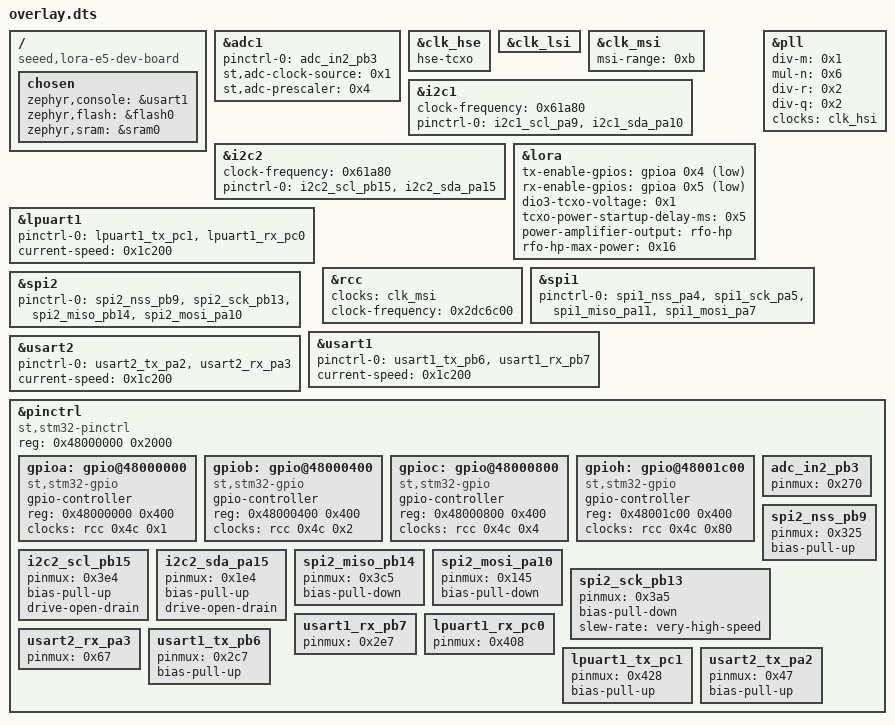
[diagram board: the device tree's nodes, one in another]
/ {
	compatible = "seeed,lora-e5-dev-board";
	chosen {
		zephyr,console = &usart1;
		zephyr,flash = &flash0;
		zephyr,sram = &sram0;
	};
};
&adc1{
	status = "okay";
	pinctrl-0 = < &adc_in2_pb3 >;
	pinctrl-names = "default";
	st,adc-clock-source = < 0x1 >;
	st,adc-prescaler = < 0x4 >;
};
&clk_hse{
	hse-tcxo;
};
&clk_lsi{
	status = "okay";
};
&clk_msi{
	msi-range = < 0xb >;
	status = "okay";
};
&i2c1{
	clock-frequency = < 0x61a80 >;
	status = "okay";
	pinctrl-0 = < &i2c1_scl_pa9 &i2c1_sda_pa10 >;
	pinctrl-names = "default";
};
&i2c2{
	clock-frequency = < 0x61a80 >;
	status = "okay";
	pinctrl-0 = < &i2c2_scl_pb15 &i2c2_sda_pa15 >;
	pinctrl-names = "default";
};
&lora{
	tx-enable-gpios = < &gpioa 0x4 0x1 >;
	rx-enable-gpios = < &gpioa 0x5 0x1 >;
	dio3-tcxo-voltage = < 0x1 >;
	tcxo-power-startup-delay-ms = < 0x5 >;
	power-amplifier-output = "rfo-hp";
	rfo-hp-max-power = < 0x16 >;
};
&lpuart1{
	status = "okay";
	pinctrl-0 = < &lpuart1_tx_pc1 &lpuart1_rx_pc0 >;
	pinctrl-names = "default";
	current-speed = < 0x1c200 >;
};
&pll{
	status = "okay";
	div-m = < 0x1 >;
	mul-n = < 0x6 >;
	div-r = < 0x2 >;
	div-q = < 0x2 >;
	clocks = < &clk_hsi >;
};
&rcc{
	clocks = < &clk_msi >;
	clock-frequency = < 0x2dc6c00 >;
};
&spi1{
	status = "okay";
	pinctrl-0 = < &spi1_nss_pa4 &spi1_sck_pa5 &spi1_miso_pa11 &spi1_mosi_pa7 >;
	pinctrl-names = "default";
};
&spi2{
	status = "okay";
	pinctrl-0 = < &spi2_nss_pb9 &spi2_sck_pb13 &spi2_miso_pb14 &spi2_mosi_pa10 >;
	pinctrl-names = "default";
};
&usart1{
	status = "okay";
	pinctrl-0 = < &usart1_tx_pb6 &usart1_rx_pb7 >;
	pinctrl-names = "default";
	current-speed = < 0x1c200 >;
};
&usart2{
	status = "okay";
	pinctrl-0 = < &usart2_tx_pa2 &usart2_rx_pa3 >;
	pinctrl-names = "default";
	current-speed = < 0x1c200 >;
};
&pinctrl{
	compatible = "st,stm32-pinctrl";
	#address-cells = < 0x1 >;
	#size-cells = < 0x1 >;
	reg = < 0x48000000 0x2000 >;
	gpioa: gpio@48000000 {
		compatible = "st,stm32-gpio";
		gpio-controller;
		#gpio-cells = < 0x2 >;
		reg = < 0x48000000 0x400 >;
		clocks = < &rcc 0x4c 0x1 >;
	};
	gpiob: gpio@48000400 {
		compatible = "st,stm32-gpio";
		gpio-controller;
		#gpio-cells = < 0x2 >;
		reg = < 0x48000400 0x400 >;
		clocks = < &rcc 0x4c 0x2 >;
	};
	gpioc: gpio@48000800 {
		compatible = "st,stm32-gpio";
		gpio-controller;
		#gpio-cells = < 0x2 >;
		reg = < 0x48000800 0x400 >;
		clocks = < &rcc 0x4c 0x4 >;
	};
	gpioh: gpio@48001c00 {
		compatible = "st,stm32-gpio";
		gpio-controller;
		#gpio-cells = < 0x2 >;
		reg = < 0x48001c00 0x400 >;
		clocks = < &rcc 0x4c 0x80 >;
	};
	adc_in2_pb3: adc_in2_pb3 {
		pinmux = < 0x270 >;
	};
	i2c2_scl_pb15: i2c2_scl_pb15 {
		pinmux = < 0x3e4 >;
		bias-pull-up;
		drive-open-drain;
	};
	i2c2_sda_pa15: i2c2_sda_pa15 {
		pinmux = < 0x1e4 >;
		bias-pull-up;
		drive-open-drain;
	};
	spi2_miso_pb14: spi2_miso_pb14 {
		pinmux = < 0x3c5 >;
		bias-pull-down;
	};
	spi2_mosi_pa10: spi2_mosi_pa10 {
		pinmux = < 0x145 >;
		bias-pull-down;
	};
	spi2_nss_pb9: spi2_nss_pb9 {
		pinmux = < 0x325 >;
		bias-pull-up;
	};
	spi2_sck_pb13: spi2_sck_pb13 {
		pinmux = < 0x3a5 >;
		bias-pull-down;
		slew-rate = "very-high-speed";
	};
	usart1_rx_pb7: usart1_rx_pb7 {
		pinmux = < 0x2e7 >;
	};
	lpuart1_rx_pc0: lpuart1_rx_pc0 {
		pinmux = < 0x408 >;
	};
	usart2_rx_pa3: usart2_rx_pa3 {
		pinmux = < 0x67 >;
	};
	usart1_tx_pb6: usart1_tx_pb6 {
		pinmux = < 0x2c7 >;
		bias-pull-up;
	};
	lpuart1_tx_pc1: lpuart1_tx_pc1 {
		pinmux = < 0x428 >;
		bias-pull-up;
	};
	usart2_tx_pa2: usart2_tx_pa2 {
		pinmux = < 0x47 >;
		bias-pull-up;
	};
};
